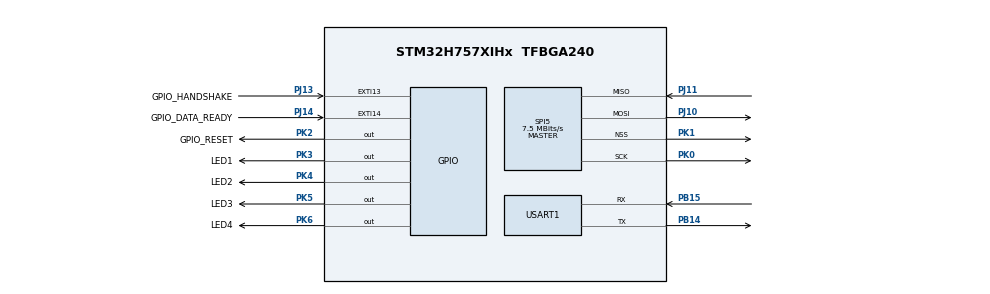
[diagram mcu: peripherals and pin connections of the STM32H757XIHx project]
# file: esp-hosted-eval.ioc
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CORTEX_M7.AccessPermission-Cortex_Memory_Protection_Unit_Region0_Settings=MPU_REGION_FULL_ACCESS
CORTEX_M7.BaseAddress-Cortex_Memory_Protection_Unit_Region0_Settings=0x30000000
CORTEX_M7.CPU_DCache=Enabled
CORTEX_M7.CPU_ICache=Enabled
CORTEX_M7.DisableExec-Cortex_Memory_Protection_Unit_Region0_Settings=MPU_INSTRUCTION_ACCESS_DISABLE
CORTEX_M7.Enable-Cortex_Memory_Protection_Unit_Region0_Settings=MPU_REGION_ENABLE
CORTEX_M7.IsBufferable-Cortex_Memory_Protection_Unit_Region0_Settings=MPU_ACCESS_BUFFERABLE
CORTEX_M7.IsShareable-Cortex_Memory_Protection_Unit_Region0_Settings=MPU_ACCESS_SHAREABLE
CORTEX_M7.MPU_Control=MPU_PRIVILEGED_DEFAULT
CORTEX_M7.Size-Cortex_Memory_Protection_Unit_Region0_Settings=MPU_REGION_SIZE_64KB
CortexM4.IPs=FATFS_M4\:I,FREERTOS_M4\:I,IWDG2\:I,RCC,USB_DEVICE_M4\:I,USB_HOST_M4\:I,WWDG2\:I,DMA,BDMA,MDMA,NVIC2\:I,DFSDM1\:I,SAI1,SAI4,DEBUG,PDM2PCM_M4\:I,PWR,RESMGR_UTILITY,SYS_M4\:I,CORTEX_M4\:I,OPENAMP_M4\:I,VREFBUF,TIM2\:I
CortexM4.Pins=PK5,PK6
CortexM7.IPs=FATFS_M7\:I,FREERTOS_M7\:I,IWDG1\:I,RCC\:I,USB_DEVICE_M7\:I,USB_HOST_M7\:I,WWDG1\:I,DMA\:I,BDMA\:I,MDMA\:I,NVIC1\:I,LTDC\:I,DSIHOST\:I,SAI1\:I,SAI4\:I,SYS\:I,USART1\:I,USB_OTG_FS\:I,USB_OTG_HS\:I,CORTEX_M7\:I,DEBUG\:I,DFSDM1,PDM2PCM_M7\:I,PWR\:I,RESMGR_UTILITY\:I,OPENAMP_M7\:I,VREFBUF\:I,TIM1\:I,SPI5\:I,STMicroelectronics.X-CUBE-AZRTOS-H7.2.0.0_M7\:I
CortexM7.Pins=PK4,PK3,PJ14,PJ13,PK2
Mcu.Family=STM32H7
Mcu.Name=STM32H757XIHx
Mcu.Package=TFBGA240
NVIC1.EXTI15_10_IRQn=true\:8\:0\:true\:false\:true\:false\:true\:true\:true
NVIC1.PriorityGroup=NVIC_PRIORITYGROUP_4
NVIC1.TIM1_UP_IRQn=true\:15\:0\:false\:false\:true\:false\:false\:true\:true
NVIC1.TimeBase=TIM1_UP_IRQn
NVIC1.TimeBaseIP=TIM1
NVIC2.PriorityGroup=NVIC_PRIORITYGROUP_4
NVIC2.TIM2_IRQn=true\:15\:0\:false\:false\:true\:false\:true\:true
NVIC2.TimeBase=TIM2_IRQn
NVIC2.TimeBaseIP=TIM2
PB14.Mode=Asynchronous
PB14.PinAttribute=CortexM7
PB14.Signal=USART1_TX
PB15.Mode=Asynchronous
PB15.PinAttribute=CortexM7
PB15.Signal=USART1_RX
PH0-OSC_IN\ (PH0).Mode=HSE-External-Oscillator
PH0-OSC_IN\ (PH0).PinAttribute=CortexM7
PH0-OSC_IN\ (PH0).Signal=RCC_OSC_IN
PH1-OSC_OUT\ (PH1).Mode=HSE-External-Oscillator
PH1-OSC_OUT\ (PH1).PinAttribute=CortexM7
PH1-OSC_OUT\ (PH1).Signal=RCC_OSC_OUT
PJ10.Mode=Full_Duplex_Master
PJ10.PinAttribute=CortexM7
PJ10.Signal=SPI5_MOSI
PJ11.Mode=Full_Duplex_Master
PJ11.PinAttribute=CortexM7
PJ11.Signal=SPI5_MISO
PJ13.GPIO_Label=GPIO_HANDSHAKE
PJ13.PinAttribute=CortexM7
PJ13.Signal=GPXTI13
PJ14.GPIO_Label=GPIO_DATA_READY
PJ14.PinAttribute=CortexM7
PJ14.Signal=GPXTI14
PK0.Mode=Full_Duplex_Master
PK0.PinAttribute=CortexM7
PK0.Signal=SPI5_SCK
PK1.Mode=NSS_Signal_Hard_Output
PK1.PinAttribute=CortexM7
PK1.Signal=SPI5_NSS
PK2.GPIO_Label=GPIO_RESET
PK2.PinAttribute=CortexM7
PK2.PinState=GPIO_PIN_SET
PK2.Signal=GPIO_Output
PK3.GPIO_Label=LED1
PK3.PinAttribute=CortexM7
PK3.Signal=GPIO_Output
PK4.GPIO_Label=LED2
PK4.PinAttribute=CortexM7
PK4.Signal=GPIO_Output
PK5.GPIO_Label=LED3
PK5.PinAttribute=CortexM4
PK5.Signal=GPIO_Output
PK6.GPIO_Label=LED4
PK6.PinAttribute=CortexM4
PK6.Signal=GPIO_Output
ProjectManager.HeapSize=M4-0x200,M7-0x200
ProjectManager.StackSize=M4-0x400,M7-0x400
ProjectManager.TargetToolchain=STM32CubeIDE
RCC.ADCFreq_Value=450000000
RCC.APB1Freq_Value=120000000
RCC.APB2Freq_Value=120000000
RCC.APB3Freq_Value=120000000
RCC.APB4Freq_Value=120000000
RCC.CortexFreq_Value=480000000
RCC.D1PPRE=RCC_APB3_DIV2
RCC.D2PPRE1=RCC_APB1_DIV2
RCC.D2PPRE2=RCC_APB2_DIV2
RCC.D3PPRE=RCC_APB4_DIV2
RCC.DIVM1=5
RCC.DIVM2=5
RCC.DIVM3=5
RCC.DIVN1=192
RCC.DIVN2=90
RCC.DIVN3=30
RCC.DIVP2=1
RCC.DIVQ1=10
RCC.DIVR3=1
RCC.DSITX_Div=2
RCC.HCLKFreq_Value=240000000
RCC.HPRE=RCC_HCLK_DIV2
RCC.HSE_VALUE=25000000
RCC.I2C123CLockSelection=RCC_I2C123CLKSOURCE_HSI
RCC.PLL2FRACN=0
RCC.PLL3FRACN=0
RCC.PLLDSINDIV=10
RCC.PLLFRACN=0
RCC.PLLSourceVirtual=RCC_PLLSOURCE_HSE
RCC.PWR_Regulator_Voltage_Scale=PWR_REGULATOR_VOLTAGE_SCALE0
RCC.SYSCLKFreq_VALUE=480000000
RCC.SYSCLKSource=RCC_SYSCLKSOURCE_PLLCLK
RCC.SupplySource=PWR_DIRECT_SMPS_SUPPLY
RCC.USBCLockSelection=RCC_USBCLKSOURCE_HSI48
RCC.USBFreq_Value=48000000
SPI5.BaudRatePrescaler=SPI_BAUDRATEPRESCALER_16
SPI5.CLKPolarity=SPI_POLARITY_HIGH
SPI5.CalculateBaudRate=7.5 MBits/s
SPI5.DataSize=SPI_DATASIZE_8BIT
SPI5.Direction=SPI_DIRECTION_2LINES
SPI5.Mode=SPI_MODE_MASTER
SPI5.NSSPMode=SPI_NSS_PULSE_DISABLE
SPI5.VirtualNSS=VM_NSSHARD
SPI5.VirtualType=VM_MASTER
STMicroelectronics.X-CUBE-AZRTOS-H7.2.0.0_IsAnAzureRtosMw=true
STMicroelectronics.X-CUBE-AZRTOS-H7.2.0.0_M7.AZRTOS_APP_MEM_ALLOCATION_METHOD=1
STMicroelectronics.X-CUBE-AZRTOS-H7.2.0.0_M7.InterfacesCcNetworkJjCustomOoInterface=true
STMicroelectronics.X-CUBE-AZRTOS-H7.2.0.0_M7.NX_APP_MEM_POOL_SIZE=30 * 1024
STMicroelectronics.X-CUBE-AZRTOS-H7.2.0.0_M7.NX_DISABLE_PACKET_CHAIN=false
STMicroelectronics.X-CUBE-AZRTOS-H7.2.0.0_M7.NX_ENABLE_INTERFACE_CAPABILITY=false
STMicroelectronics.X-CUBE-AZRTOS-H7.2.0.0_M7.NX_MAX_PHYSICAL_INTERFACES=4
STMicroelectronics.X-CUBE-AZRTOS-H7.2.0.0_M7.NetXDuoCcNetworkJjNetXDuoJjAddonsOoAutoIP=true
STMicroelectronics.X-CUBE-AZRTOS-H7.2.0.0_M7.NetXDuoCcNetworkJjNetXDuoJjAddonsOoCloud=true
STMicroelectronics.X-CUBE-AZRTOS-H7.2.0.0_M7.NetXDuoCcNetworkJjNetXDuoJjAddonsOoDHCPOoClient=true
STMicroelectronics.X-CUBE-AZRTOS-H7.2.0.0_M7.NetXDuoCcNetworkJjNetXDuoJjAddonsOoDNS=true
STMicroelectronics.X-CUBE-AZRTOS-H7.2.0.0_M7.NetXDuoCcNetworkJjNetXDuoJjAddonsOoMQTT=true
STMicroelectronics.X-CUBE-AZRTOS-H7.2.0.0_M7.NetXDuoCcNetworkJjNetXDuoJjAddonsOoPPP=true
STMicroelectronics.X-CUBE-AZRTOS-H7.2.0.0_M7.NetXDuoCcNetworkJjNetXDuoJjAddonsOoSNTP=true
STMicroelectronics.X-CUBE-AZRTOS-H7.2.0.0_M7.NetXDuoCcNetworkJjNetXDuoJjAddonsOoWebOoClient=true
STMicroelectronics.X-CUBE-AZRTOS-H7.2.0.0_M7.NetXDuoCcNetworkJjNetXDuoJjAddonsOomDNS=true
STMicroelectronics.X-CUBE-AZRTOS-H7.2.0.0_M7.NetXDuoCcNetworkJjNetXDuoJjCrypto=true
STMicroelectronics.X-CUBE-AZRTOS-H7.2.0.0_M7.NetXDuoCcNetworkJjNetXDuoJjNXOoCore=true
STMicroelectronics.X-CUBE-AZRTOS-H7.2.0.0_M7.NetXDuoCcNetworkJjNetXDuoJjTLS=true
STMicroelectronics.X-CUBE-AZRTOS-H7.2.0.0_M7.NetXDuoCcNetworkJjNetXDuoJjTraceXOoSupport=true
STMicroelectronics.X-CUBE-AZRTOS-H7.2.0.0_M7.TX_THREAD_USER_EXTENSION=VOID *txfr_thread_ptr;
STMicroelectronics.X-CUBE-AZRTOS-H7.2.0.0_M7.ThreadXCcRTOSJjThreadXJjCore=true
STMicroelectronics.X-CUBE-AZRTOS-H7.2.0.0_M7.ThreadXCcRTOSJjThreadXJjLowOoPowerOosupport=true
STMicroelectronics.X-CUBE-AZRTOS-H7.2.0.0_M7.ThreadXCcRTOSJjThreadXJjPerformanceInfo=true
STMicroelectronics.X-CUBE-AZRTOS-H7.2.0.0_M7.ThreadXCcRTOSJjThreadXJjTraceXOosupport=true
USART1.VirtualMode-Asynchronous=VM_ASYNC
VP_STMicroelectronics.X-CUBE-AZRTOS-H7_M7_VS_NetworkJjInterfaces_2.0.0_2.0.0.Mode=NetworkJjInterfaces
VP_STMicroelectronics.X-CUBE-AZRTOS-H7_M7_VS_NetworkJjNetXDuo_6.1.7_2.0.0.Mode=NetworkJjNetXDuo
VP_STMicroelectronics.X-CUBE-AZRTOS-H7_M7_VS_RTOSJjThreadX_6.1.7_2.0.0.Mode=RTOSJjThreadX
VP_SYS_M4_VS_tim2.Mode=TIM2
VP_SYS_VS_tim1.Mode=TIM1
board=STM32H757I-EVAL

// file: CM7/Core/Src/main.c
/* USER CODE BEGIN Header */
/**
  ******************************************************************************
  * @file           : main.c
  * @brief          : Main program body
  ******************************************************************************
  * @attention
  *
  * Copyright (c) 2022 STMicroelectronics.
  * All rights reserved.
  *
  * This software is licensed under terms that can be found in the LICENSE file
  * in the root directory of this software component.
  * If no LICENSE file comes with this software, it is provided AS-IS.
  *
  ******************************************************************************
  */
/* USER CODE END Header */
#include "main.h"
#include "app_threadx.h"
#include "spi.h"
#include "usart.h"
#include "gpio.h"

/* USER CODE BEGIN Includes */
#include "spi.h"
/* USER CODE END Includes */

/* USER CODE BEGIN PD */

#ifndef HSEM_ID_0
#define HSEM_ID_0 (0U) /* HW semaphore 0*/
#endif
/* USER CODE END PD */

void SystemClock_Config(void);
static void MPU_Config(void);

/* USER CODE BEGIN 0 */
/**
  * @brief  Application ThreadX with FreeRTOS Wrapper Initialization.
  * @param memory_ptr: memory pointer
  * @retval int
  */
UINT App_TX_FreeRTOS_Init(void)
{
  UINT ret = TX_SUCCESS;
  /* USER CODE BEGIN  App_TX_FreeRTOS_Init */
  tx_kernel_enter();
  /* USER CODE END  App_TX_FreeRTOS_Init */
  return ret;
}
/* USER CODE END 0 */

int main(void)
{
/* USER CODE BEGIN Boot_Mode_Sequence_0 */
  int32_t timeout;
/* USER CODE END Boot_Mode_Sequence_0 */

  /* MPU Configuration--------------------------------------------------------*/
  MPU_Config();

  /* Enable I-Cache---------------cmsis------------------------------------------*/
  SCB_EnableICache();

  /* Enable D-Cache---------------------------------------------------------*/
  SCB_EnableDCache();

/* USER CODE BEGIN Boot_Mode_Sequence_1 */
  /* Wait until CPU2 boots and enters in stop mode or timeout*/
  timeout = 0xFFFF;
  while((__HAL_RCC_GET_FLAG(RCC_FLAG_D2CKRDY) != RESET) && (timeout-- > 0));
  if ( timeout < 0 )
  {
  Error_Handler();
  }
/* USER CODE END Boot_Mode_Sequence_1 */
  /* MCU Configuration--------------------------------------------------------*/

  /* Reset of all peripherals, Initializes the Flash interface and the Systick. */
  HAL_Init();

  /* Configure the system clock */
  SystemClock_Config();
/* USER CODE BEGIN Boot_Mode_Sequence_2 */
/* When system initialization is finished, Cortex-M7 will release Cortex-M4 by means of
HSEM notification */
/*HW semaphore Clock enable*/
__HAL_RCC_HSEM_CLK_ENABLE();
/*Take HSEM */
HAL_HSEM_FastTake(HSEM_ID_0);
/*Release HSEM in order to notify the CPU2(CM4)*/
HAL_HSEM_Release(HSEM_ID_0,0);
/* wait until CPU2 wakes up from stop mode */
timeout = 0xFFFF;
while((__HAL_RCC_GET_FLAG(RCC_FLAG_D2CKRDY) == RESET) && (timeout-- > 0));
if ( timeout < 0 )
{
Error_Handler();
}
/* USER CODE END Boot_Mode_Sequence_2 */

  /* Initialize all configured peripherals */
  MX_GPIO_Init();
  MX_USART1_UART_Init();
  MX_SPI5_Init();
  /* USER CODE BEGIN 2 */
//  App_TX_FreeRTOS_Init();
  /* USER CODE END 2 */

  MX_ThreadX_Init();
  //MX_FREERTOS_Init();
  /* We should never get here as control is now taken by the scheduler */
  /* Infinite loop */
  while (1)
  {

  }
}

void SystemClock_Config(void)
{
  RCC_OscInitTypeDef RCC_OscInitStruct = {0};
  RCC_ClkInitTypeDef RCC_ClkInitStruct = {0};

  /** Supply configuration update enable
  */
  HAL_PWREx_ConfigSupply(PWR_DIRECT_SMPS_SUPPLY);

  /** Configure the main internal regulator output voltage
  */
  __HAL_PWR_VOLTAGESCALING_CONFIG(PWR_REGULATOR_VOLTAGE_SCALE0);

  while(!__HAL_PWR_GET_FLAG(PWR_FLAG_VOSRDY)) {}

  /** Initializes the RCC Oscillators according to the specified parameters
  * in the RCC_OscInitTypeDef structure.
  */
  RCC_OscInitStruct.OscillatorType = RCC_OSCILLATORTYPE_HSE;
  RCC_OscInitStruct.HSEState = RCC_HSE_ON;
  RCC_OscInitStruct.PLL.PLLState = RCC_PLL_ON;
  RCC_OscInitStruct.PLL.PLLSource = RCC_PLLSOURCE_HSE;
  RCC_OscInitStruct.PLL.PLLM = 5;
  RCC_OscInitStruct.PLL.PLLN = 192;
  RCC_OscInitStruct.PLL.PLLP = 2;
  RCC_OscInitStruct.PLL.PLLQ = 10;
  RCC_OscInitStruct.PLL.PLLR = 2;
  RCC_OscInitStruct.PLL.PLLRGE = RCC_PLL1VCIRANGE_2;
  RCC_OscInitStruct.PLL.PLLVCOSEL = RCC_PLL1VCOWIDE;
  RCC_OscInitStruct.PLL.PLLFRACN = 0;
  if (HAL_RCC_OscConfig(&RCC_OscInitStruct) != HAL_OK)
  {
    Error_Handler();
  }

  /** Initializes the CPU, AHB and APB buses clocks
  */
  RCC_ClkInitStruct.ClockType = RCC_CLOCKTYPE_HCLK|RCC_CLOCKTYPE_SYSCLK
                              |RCC_CLOCKTYPE_PCLK1|RCC_CLOCKTYPE_PCLK2
                              |RCC_CLOCKTYPE_D3PCLK1|RCC_CLOCKTYPE_D1PCLK1;
  RCC_ClkInitStruct.SYSCLKSource = RCC_SYSCLKSOURCE_PLLCLK;
  RCC_ClkInitStruct.SYSCLKDivider = RCC_SYSCLK_DIV1;
  RCC_ClkInitStruct.AHBCLKDivider = RCC_HCLK_DIV2;
  RCC_ClkInitStruct.APB3CLKDivider = RCC_APB3_DIV2;
  RCC_ClkInitStruct.APB1CLKDivider = RCC_APB1_DIV2;
  RCC_ClkInitStruct.APB2CLKDivider = RCC_APB2_DIV2;
  RCC_ClkInitStruct.APB4CLKDivider = RCC_APB4_DIV2;

  if (HAL_RCC_ClockConfig(&RCC_ClkInitStruct, FLASH_LATENCY_4) != HAL_OK)
  {
    Error_Handler();
  }
}

/* MPU Configuration */

void MPU_Config(void)
{
  MPU_Region_InitTypeDef MPU_InitStruct = {0};

  /* Disables the MPU */
  HAL_MPU_Disable();

  /** Initializes and configures the Region and the memory to be protected
  */
  MPU_InitStruct.Enable = MPU_REGION_ENABLE;
  MPU_InitStruct.Number = MPU_REGION_NUMBER0;
  MPU_InitStruct.BaseAddress = 0x30000000;
  MPU_InitStruct.Size = MPU_REGION_SIZE_64KB;
  MPU_InitStruct.SubRegionDisable = 0x0;
  MPU_InitStruct.TypeExtField = MPU_TEX_LEVEL0;
  MPU_InitStruct.AccessPermission = MPU_REGION_FULL_ACCESS;
  MPU_InitStruct.DisableExec = MPU_INSTRUCTION_ACCESS_DISABLE;
  MPU_InitStruct.IsShareable = MPU_ACCESS_SHAREABLE;
  MPU_InitStruct.IsCacheable = MPU_ACCESS_NOT_CACHEABLE;
  MPU_InitStruct.IsBufferable = MPU_ACCESS_BUFFERABLE;

  HAL_MPU_ConfigRegion(&MPU_InitStruct);
  /* Enables the MPU */
  HAL_MPU_Enable(MPU_PRIVILEGED_DEFAULT);

}

void HAL_TIM_PeriodElapsedCallback(TIM_HandleTypeDef *htim)
{
  if (htim->Instance == TIM1) {
    HAL_IncTick();
  }
}

void Error_Handler(void)
{
  __disable_irq();
  while (1)
  {
  }
}
